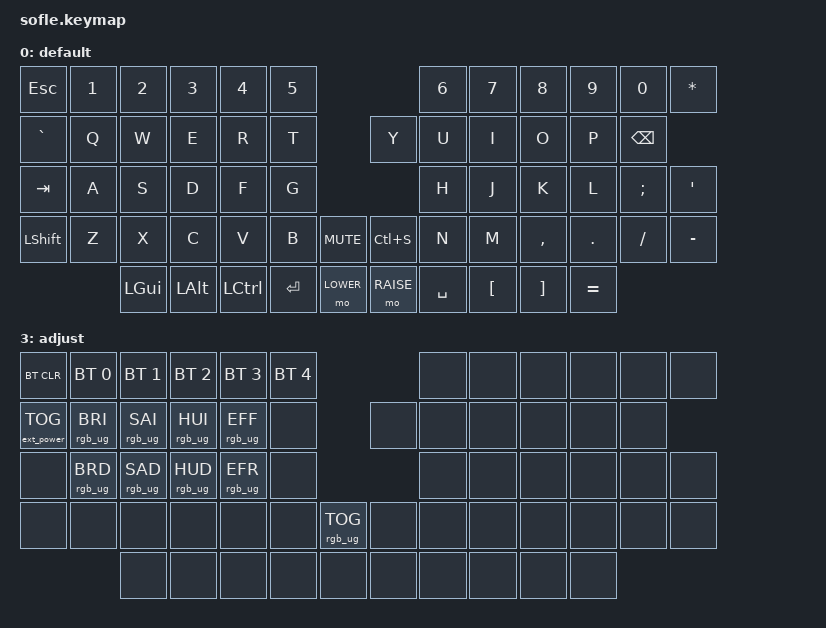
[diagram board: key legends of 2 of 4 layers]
/*
 * Copyright (c) 2020 The ZMK Contributors
 *
 * SPDX-License-Identifier: MIT
 */

#include <behaviors.dtsi>
#include <dt-bindings/zmk/keys.h>
#include <dt-bindings/zmk/bt.h>
#include <dt-bindings/zmk/rgb.h>
#include <dt-bindings/zmk/ext_power.h>
#include <dt-bindings/led/led.h>

&led_strip {
    chain-length = <30>;
};

#define BASE 0
#define LOWER 1
#define RAISE 2
#define ADJUST 3

/ {

   // Activate ADJUST layer by pressing raise and lower
    conditional_layers {
        compatible = "zmk,conditional-layers";
        adjust_layer {
            if-layers = <LOWER RAISE>;
            then-layer = <ADJUST>;
        };
    };

    keymap {
        compatible = "zmk,keymap";

        default_layer {
            display-name = "default";
// ┌────┬────┬────┬────┬────┬────┐           ┌────┬────┬────┬────┬────┬────┐
// │ESC │ 1  │ 2  │ 3  │ 4  │ 5  │           │ 6  │ 7  │ 8  │ 9  │ 0  │ *  │
// ├────┼────┼────┼────┼────┼────┤           ├────┼────┼────┼────┼────┼────┤
// │ `  │ Q  │ W  │ E  │ R  │ T  │           │ Y  │ U  │ I  │ O  │ P  │BSP │
// ├────┼────┼────┼────┼────┼────┤           ├────┼────┼────┼────┼────┼────┤
// │TAB │ A  │ S  │ D  │ F  │ G  │           │ H  │ J  │ K  │ L  │ ;  │ '  │
// ├────┼────┼────┼────┼────┼────┼────┬──────┼────┼────┼────┼────┼────┼────┤
// │SHFT│ Z  │ X  │ C  │ V  │ B  │MUTE│ SAVE │ N  │ M  │ ,  │ .  │ /  │ -  │
// └────┴────┴────┴────┴────┴────┴────┴──────┴────┴────┴────┴────┴────┴────┘
  //      GUI  ALT  CTRL  ENTER LOWER      RAISE SPACE [ ] =
            bindings = <
&kp ESC &kp N1 &kp N2   &kp N3   &kp N4    &kp N5                           &kp N6 &kp N7    &kp N8    &kp N9   &kp N0   &kp ASTERISK
&kp GRAVE   &kp Q  &kp W    &kp E    &kp R     &kp T                            &kp Y  &kp U     &kp I     &kp O    &kp P    &kp BSPC
&kp TAB   &kp A  &kp S    &kp D    &kp F     &kp G                            &kp H  &kp J     &kp K     &kp L    &kp SEMI &kp SQT
&kp LSHFT &kp Z  &kp X    &kp C    &kp V     &kp B      &kp C_MUTE &kp LC(S)      &kp N  &kp M     &kp COMMA &kp DOT  &kp FSLH &kp MINUS
                 &kp LGUI &kp LALT &kp LCTRL &kp RET  &mo LOWER    &mo RAISE  &kp SPACE  &kp LBKT &kp RBKT  &kp EQUAL
            >;

            sensor-bindings = <&inc_dec_kp C_VOL_DN C_VOL_UP &inc_dec_kp PG_UP PG_DN>;
        };

        lower_layer {
            display-name = "lower";
// ┌────┬────┬────┬────┬────┬────┐           ┌────┬────┬────┬────┬────┬────┐
// │    │ F1 │ F2 │ F3 │ F4 │ F5 │           │ F6 │ F7 │ F8 │ F9 │F10 │F11 │
// ├────┼────┼────┼────┼────┼────┤           ├────┼────┼────┼────┼────┼────┤
// │ `  │ 1  │ 2  │ 3  │ 4  │ 5  │           │ 6  │ 7  │ 8  │ 9  │ 0  │F12 │
// ├────┼────┼────┼────┼────┼────┤           ├────┼────┼────┼────┼────┼────┤
// │    │ !  │ @  │ #  │ $  │ %  │           │ ^  │ &  │ *  │ (  │ )  │ |  │
// ├────┼────┼────┼────┼────┼────┼────┬──────┼────┼────┼────┼────┼────┼────┤
// │    │ =  │ -  │ +  │ {  │ }  │ // │ FIND │ RPL│ [  │ ]  │ \  │    │
// └────┴────┴────┴────┴────┴────┴────┴──────┴────┴────┴────┴────┴────┴────┘
            bindings = <
&trans    &kp F1    &kp F2    &kp F3      &kp F4    &kp F5                    &kp F6    &kp F7   &kp F8    &kp F9    &kp F10   &kp F11

&kp GRAVE &kp N1    &kp N2    &kp N3      &kp N4    &kp N5                    &kp N6    &kp N7   &kp N8    &kp N9    &kp N0    &kp F12

// símbolos bien organizados para código
&trans    &kp EXCL  &kp AT    &kp HASH    &kp DLLR  &kp PRCNT                 &kp CARET &kp AMPS &kp ASTRK &kp LPAR  &kp RPAR  &kp PIPE

// núcleo de programación
&trans    &kp EQUAL &kp MINUS &kp PLUS    &kp LBRC  &kp RBRC   &kp LC(SLASH)  &kp LC(F)  &kp LC(H) &kp LBKT  &kp RBKT &kp BSLH  &trans

                &trans    &trans      &trans    &trans     &trans &trans  &trans    &trans   &trans    &trans
    >;

            sensor-bindings = <&inc_dec_kp LEFT RIGHT &inc_dec_kp LC(LEFT) LC(RIGHT)>;
        };

        raise_layer {
            display-name = "raise";
// ┌────┬────┬────┬────┬────┬────┐           ┌────┬────┬────┬────┬────┬────┐
// │BT  │BT1 │BT2 │BT3 │BT4 │BT5 │           │    │    │    │    │    │    │
// ├────┼────┼────┼────┼────┼────┤           ├────┼────┼────┼────┼────┼────┤
// │    │INS │PSCR│TERM│CMD │FMT │           │PGUP│TAB←│ ↑  │TAB→│HOME│END │
// ├────┼────┼────┼────┼────┼────┤           ├────┼────┼────┼────┼────┼────┤
// │    │ALT │CTRL│SHFT│UNDO│REDO│           │PGDN│ ←  │ ↓  │ →  │DEL │BSP │
// ├────┼────┼────┼────┼────┼────┼────┬──────┼────┼────┼────┼────┼────┼────┤
// │    │COPY│PAST│CUT │ ALL│    │    │      │SEL←│SEL→│    │    │    │    │
// └────┴────┴────┴────┴────┴────┴────┴──────┴────┴────┴────┴────┴────┴────┘
           bindings = <

// Bluetooth (igual lo dejamos)
&bt BT_CLR &bt BT_SEL 0 &bt BT_SEL 1 &bt BT_SEL 2 &bt BT_SEL 3 &bt BT_SEL 4        &trans &trans &trans &trans &trans &trans

// navegación + IDE
&trans     &kp INS      &kp PSCRN    &kp LC(GRAVE) &kp LS(LC(P)) &kp LS(LA(F))     &kp PG_UP &kp LC(PG_UP) &kp UP   &kp LC(PG_DN) &kp HOME &kp END

// navegación avanzada
&trans     &kp LALT     &kp LCTRL    &kp LSHFT     &kp LC(Z)     &kp LC(Y)          &kp PG_DN &kp LEFT      &kp DOWN &kp RIGHT     &kp DEL  &kp BSPC

// edición rápida
&trans     &kp LC(C)    &kp LC(V)    &kp LC(X)     &kp LC(A)     &trans             &trans    &kp LS(LEFT)  &kp LS(RIGHT) &trans &trans &trans

                &trans       &trans       &trans       &trans        &trans  &trans  &trans    &trans    &trans   &trans
    >;

            sensor-bindings = <&inc_dec_kp UP DOWN &inc_dec_kp PG_UP PG_DN>;
        };

        adjust_layer {
// ----------------------------------------------------------------------------------------------------------------------------
// | BTCLR  |  BT1    |  BT2    |   BT3   |   BT4   |   BT5   |                  |      |      |       |      |       |       |
// | EXTPWR |RGB BRI+ |RGB SAT+ |RGB HUE+ |RGB ANI+ |         |                  |      |      |       |      |       |       |
// |        |RGB BRI- |RGB SAT- |RGB HUE- |RGB ANI- |         |                  |      |      |       |      |       |       |
// |        |         |         |         |         |         | RGB_TOG | |      |      |      |       |      |       |       |
//                    |         |         |         |         |         | |      |      |      |       |      |
            display-name = "adjust";
            bindings = <
&bt BT_CLR        &bt BT_SEL 0    &bt BT_SEL 1    &bt BT_SEL 2    &bt BT_SEL 3    &bt BT_SEL 4                            &none &none &none &none &none &none
&ext_power EP_TOG &rgb_ug RGB_BRI &rgb_ug RGB_SAI &rgb_ug RGB_HUI &rgb_ug RGB_EFF &none                         &none &none &none &none &none &none
&none             &rgb_ug RGB_BRD &rgb_ug RGB_SAD &rgb_ug RGB_HUD &rgb_ug RGB_EFR &none                                   &none &none &none &none &none &none
&none             &none           &none           &none           &none           &none            &rgb_ug RGB_TOG &none  &none &none &none &none &none &none
                                  &none           &none           &none           &none            &none           &none  &none &none &none &none
            >;
        };

    };
};
